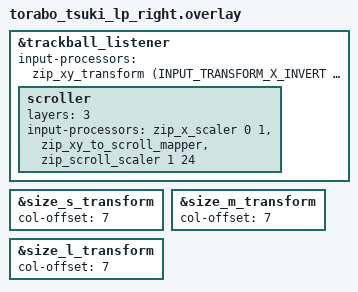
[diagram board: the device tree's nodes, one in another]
#include "torabo_tsuki_lp.dtsi"
#include <input/processors.dtsi>
#include <dt-bindings/zmk/input_transform.h>

&trackball_listener {
    // ベースの挙動（変更なし）
    input-processors = <
        &zip_xy_transform (INPUT_TRANSFORM_X_INVERT | INPUT_TRANSFORM_Y_INVERT)
    >;

    scroller {
        layers = <3>;
        input-processors = <
            // 1. まず横方向(X)の動きを「0」にして消す (分子0 / 分母1)
            &zip_x_scaler 0 1
            
            // 2. 残った縦方向(Y)だけをスクロールに変換する
            &zip_xy_to_scroll_mapper
            
            // 3. 速度調整（必要に応じて数字を変更）
            &zip_scroll_scaler 1 24
        >;
    };
};

&size_s_transform {
    col-offset = <7>;
};

&size_m_transform {
    col-offset = <7>;
};

&size_l_transform {
    col-offset = <7>;
};
